# nrf52820 register map
Vendor: Nordic Semiconductor; Series: nrf52; File version: 1
CPU: CM4 r0p1, little endian, MPU, no FPU, 3 interrupt priority bits
Registers are 32-bit, read-write, reset 0x0 unless marked. A register's access mark holds for its fields unless they carry their own. Offsets are from the block's base; [hi:lo] are bit positions; lines under a group give offsets from that group; {n}, {i} and the like mark numbered series.

## FICR — Factory information configuration registers
Base 0x10000000
0x10 CODEPAGESIZE ro reset 0xFFFFFFFF — Code memory page size
0x14 CODESIZE ro reset 0xFFFFFFFF — Code memory size
  [31:0] CODESIZE — Code memory size in number of pages
{0x60+4i} DEVICEID[{i}] (i=0..1) ro reset 0xFFFFFFFF — Description collection: Device identifier
  [31:0] DEVICEID — 64 bit unique device identifier
{0x80+4i} ER[{i}] (i=0..3) ro reset 0xFFFFFFFF — Description collection: Encryption root, word n
  [31:0] ER — Encryption root, word n
{0x90+4i} IR[{i}] (i=0..3) ro reset 0xFFFFFFFF — Description collection: Identity Root, word n
  [31:0] IR — Identity Root, word n
0xA0 DEVICEADDRTYPE ro reset 0xFFFFFFFF — Device address type
  [0] DEVICEADDRTYPE
    0=Public address; 1=Random address
{0xA4+4i} DEVICEADDR[{i}] (i=0..1) ro reset 0xFFFFFFFF — Description collection: Device address n
  [31:0] DEVICEADDR — 48 bit device address
0x100 INFO group — Device info
  0x00 PART ro reset 0x52820 — Part code
    [31:0] PART
      0x52820=N52820 (nRF52820); 0x52833=N52833 (nRF52833); 0x52840=N52840 (nRF52840); 0xFFFFFFFF=Unspecified
  0x04 VARIANT ro reset 0xFFFFFFFF — Build code (hardware version and production configuration)
    [31:0] VARIANT — Build code (hardware version and production configuration). Encoded as ASCII.
      0x41414141=AAAA; 0x41414243=AABC; 0x41414330=AAC0; 0x41414331=AAC1; 0x41414430=AAD0; 0xFFFFFFFF=Unspecified
  0x08 PACKAGE ro reset 0xFFFFFFFF — Package option
    [31:0] PACKAGE
      0x2007=QD (QDxx - 5x5 40-pin QFN); 0xFFFFFFFF=Unspecified
  0x0C RAM ro reset 0xFFFFFFFF — RAM variant
    [31:0] RAM
      16=K16 (16 kB RAM); 32=K32 (32 kB RAM); 64=K64 (64 kB RAM); 128=K128 (128 kB RAM); 0x100=K256 (256 kB RAM); 0xFFFFFFFF=Unspecified
  0x10 FLASH ro reset 0xFFFFFFFF — Flash variant
    [31:0] FLASH
      128=K128 (128 kB FLASH); 0x100=K256 (256 kB FLASH); 0x200=K512 (512 kB FLASH); 0x400=K1024 (1 MB FLASH); 0x800=K2048 (2 MB FLASH); 0xFFFFFFFF=Unspecified
{0x350+4i} PRODTEST[{i}] (i=0..2) ro reset 0xFFFFFFFF — Description collection: Production test signature n
  [31:0] PRODTEST — Production test signature n
    0xBB42319F=Done (Production tests done); 0xFFFFFFFF=NotDone (Production tests not done)
0x404 TEMP group — Registers storing factory TEMP module linearization coefficients
  {0x0+4j} A{j} ro reset 0xFFFFFFFF (j=0..5) — Slope definition A{j}
    [11:0] A — A (slope definition) register.
  {0x18+4j} B{j} ro reset 0xFFFFFFFF (j=0..5) — Y-intercept B{j}
    [13:0] B — B (y-intercept)
  {0x30+4j} T{j} ro reset 0xFFFFFFFF (j=0..4) — Segment end T{j}
    [7:0] T — T (segment end) register

## UICR — User information configuration registers
Base 0x10001000
{0x14+4i} NRFFW[{i}] (i=0..12) reset 0xFFFFFFFF — Description collection: Reserved for Nordic firmware design
  [31:0] NRFFW — Reserved for Nordic firmware design
{0x50+4i} NRFHW[{i}] (i=0..11) reset 0xFFFFFFFF — Description collection: Reserved for Nordic hardware design
  [31:0] NRFHW — Reserved for Nordic hardware design
{0x80+4i} CUSTOMER[{i}] (i=0..31) reset 0xFFFFFFFF — Description collection: Reserved for customer
  [31:0] CUSTOMER — Reserved for customer
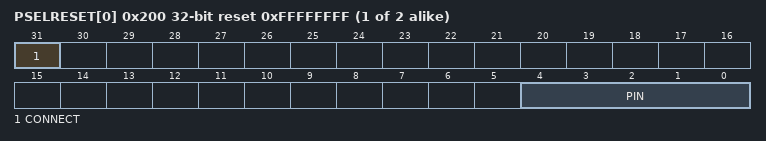
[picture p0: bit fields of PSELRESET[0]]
{0x200+4i} PSELRESET[{i}] (i=0..1) reset 0xFFFFFFFF — Description collection: Mapping of the nRESET function (see POWER chapter for details)
  [31] CONNECT — Connection
    1=Disconnected; 0=Connected
  [4:0] PIN — GPIO pin number onto which nRESET is exposed
0x208 APPROTECT reset 0xFFFFFFFF — Access port protection
  [7:0] PALL — Enable or disable access port protection.
    255=Disabled (Hardware disable of access port protection for devices where access port protection is controlled by hardware); 90=HwDisabled (Hardware disable of access port protection for devices where access port protection is controlled by hardware and software); 0=Enabled
0x210 DEBUGCTRL reset 0xFFFFFFFF — Processor debug control
  [15:8] CPUFPBEN — Configure CPU flash patch and breakpoint (FPB) unit behavior
    255=Enabled (Enable CPU FPB unit (default behavior)); 0=Disabled (Disable CPU FPB unit. Writes into the FPB registers will be ignored.)
0x304 REGOUT0 reset 0xFFFFFFFF — Output voltage from REG0 regulator stage. The maximum output voltage from this stage is given as VDDH - V_VDDH-VDD.
  [2:0] VOUT — Output voltage from REG0 regulator stage.
    0=1V8 (1.8 V); 1=2V1 (2.1 V); 2=2V4 (2.4 V); 3=2V7 (2.7 V); 4=3V0 (3.0 V); 5=3V3 (3.3 V); 7=DEFAULT (Default voltage: 1.8 V)

## Notices in the file
Copyright (c) 2010 - 2025, Nordic Semiconductor ASA All rights reserved.
SPDX-License-Identifier: BSD-3-Clause
Redistribution and use in source and binary forms, with or without
modification, are permitted provided that the following conditions are met:
1. Redistributions of source code must retain the above copyright notice, this
list of conditions and the following disclaimer.
2. Redistributions in binary form must reproduce the above copyright
notice, this list of conditions and the following disclaimer in the
documentation and/or other materials provided with the distribution.
3. Neither the name of Nordic Semiconductor ASA nor the names of its
contributors may be used to endorse or promote products derived from this
software without specific prior written permission.
THIS SOFTWARE IS PROVIDED BY THE COPYRIGHT HOLDERS AND CONTRIBUTORS "AS IS"
AND ANY EXPRESS OR IMPLIED WARRANTIES, INCLUDING, BUT NOT LIMITED TO, THE
IMPLIED WARRANTIES OF MERCHANTABILITY, AND FITNESS FOR A PARTICULAR PURPOSE
ARE DISCLAIMED. IN NO EVENT SHALL NORDIC SEMICONDUCTOR ASA OR CONTRIBUTORS BE
LIABLE FOR ANY DIRECT, INDIRECT, INCIDENTAL, SPECIAL, EXEMPLARY, OR
CONSEQUENTIAL DAMAGES (INCLUDING, BUT NOT LIMITED TO, PROCUREMENT OF
SUBSTITUTE GOODS OR SERVICES; LOSS OF USE, DATA, OR PROFITS; OR BUSINESS
INTERRUPTION) HOWEVER CAUSED AND ON ANY THEORY OF LIABILITY, WHETHER IN
CONTRACT, STRICT LIABILITY, OR TORT (INCLUDING NEGLIGENCE OR OTHERWISE)
ARISING IN ANY WAY OUT OF THE USE OF THIS SOFTWARE, EVEN IF ADVISED OF THE
POSSIBILITY OF SUCH DAMAGE.
